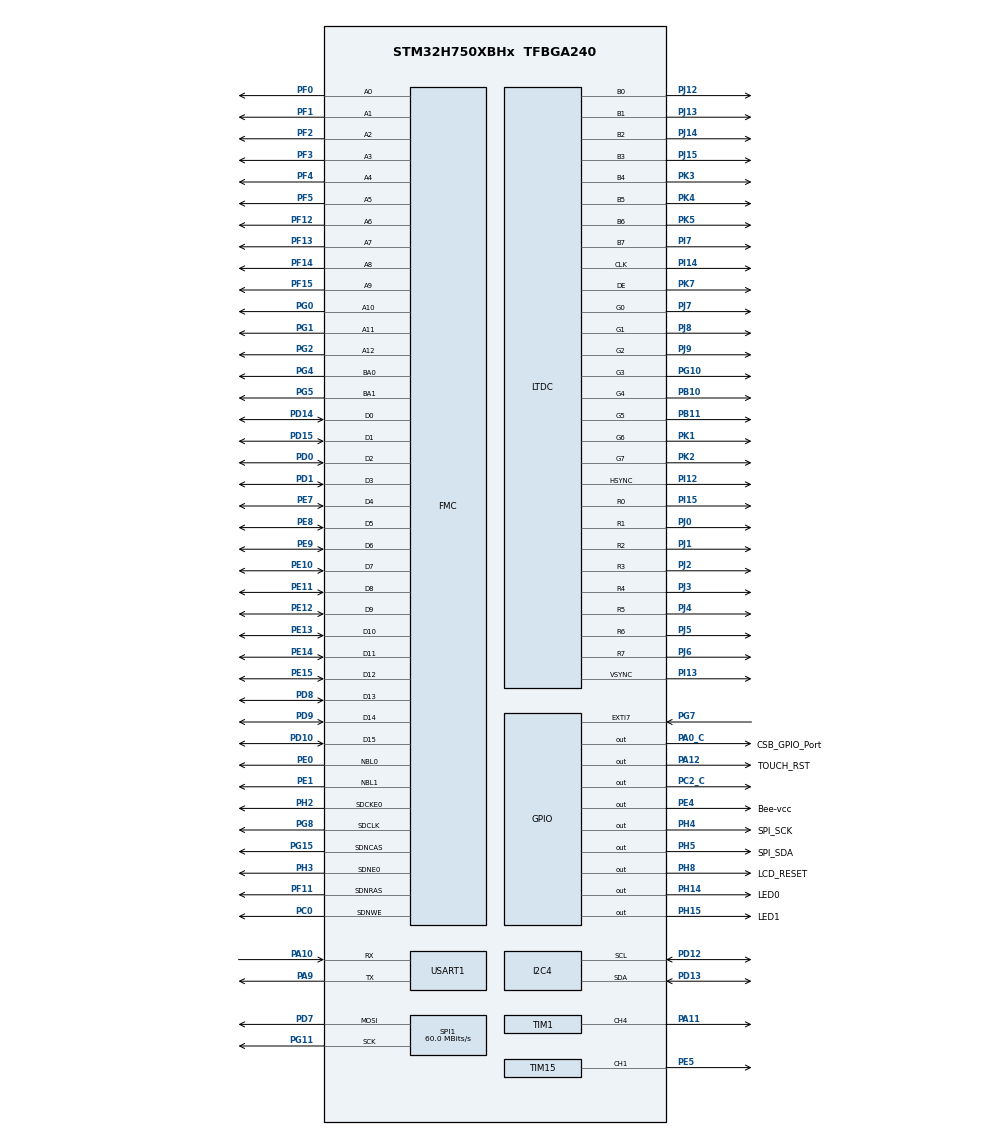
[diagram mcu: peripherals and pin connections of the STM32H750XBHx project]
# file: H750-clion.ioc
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CORTEX_M7.AccessPermission-Cortex_Memory_Protection_Unit_Region0_Settings=MPU_REGION_FULL_ACCESS
CORTEX_M7.BaseAddress-Cortex_Memory_Protection_Unit_Region0_Settings=0xC0000000
CORTEX_M7.CPU_DCache=Enabled
CORTEX_M7.CPU_ICache=Enabled
CORTEX_M7.Enable-Cortex_Memory_Protection_Unit_Region0_Settings=MPU_REGION_ENABLE
CORTEX_M7.IsCacheable-Cortex_Memory_Protection_Unit_Region0_Settings=MPU_ACCESS_CACHEABLE
CORTEX_M7.MPU_Control=MPU_PRIVILEGED_DEFAULT
CORTEX_M7.Size-Cortex_Memory_Protection_Unit_Region0_Settings=MPU_REGION_SIZE_32MB
DMA2D.ColorMode=DMA2D_OUTPUT_RGB565
Dma.Request0=USART1_RX
Dma.Request1=USART1_TX
Dma.USART1_RX.0.Direction=DMA_PERIPH_TO_MEMORY
Dma.USART1_RX.0.EventEnable=DISABLE
Dma.USART1_RX.0.FIFOMode=DMA_FIFOMODE_DISABLE
Dma.USART1_RX.0.Instance=DMA1_Stream0
Dma.USART1_RX.0.MemDataAlignment=DMA_MDATAALIGN_BYTE
Dma.USART1_RX.0.MemInc=DMA_MINC_ENABLE
Dma.USART1_RX.0.Mode=DMA_NORMAL
Dma.USART1_RX.0.PeriphDataAlignment=DMA_PDATAALIGN_BYTE
Dma.USART1_RX.0.PeriphInc=DMA_PINC_DISABLE
Dma.USART1_RX.0.Polarity=HAL_DMAMUX_REQ_GEN_RISING
Dma.USART1_RX.0.Priority=DMA_PRIORITY_LOW
Dma.USART1_RX.0.RequestNumber=1
Dma.USART1_RX.0.SignalID=NONE
Dma.USART1_RX.0.SyncEnable=DISABLE
Dma.USART1_RX.0.SyncPolarity=HAL_DMAMUX_SYNC_NO_EVENT
Dma.USART1_RX.0.SyncRequestNumber=1
Dma.USART1_RX.0.SyncSignalID=NONE
Dma.USART1_TX.1.Direction=DMA_MEMORY_TO_PERIPH
Dma.USART1_TX.1.EventEnable=DISABLE
Dma.USART1_TX.1.FIFOMode=DMA_FIFOMODE_DISABLE
Dma.USART1_TX.1.Instance=DMA1_Stream1
Dma.USART1_TX.1.MemDataAlignment=DMA_MDATAALIGN_BYTE
Dma.USART1_TX.1.MemInc=DMA_MINC_ENABLE
Dma.USART1_TX.1.Mode=DMA_NORMAL
Dma.USART1_TX.1.PeriphDataAlignment=DMA_PDATAALIGN_BYTE
Dma.USART1_TX.1.PeriphInc=DMA_PINC_DISABLE
Dma.USART1_TX.1.Polarity=HAL_DMAMUX_REQ_GEN_RISING
Dma.USART1_TX.1.Priority=DMA_PRIORITY_LOW
Dma.USART1_TX.1.RequestNumber=1
Dma.USART1_TX.1.SignalID=NONE
Dma.USART1_TX.1.SyncEnable=DISABLE
Dma.USART1_TX.1.SyncPolarity=HAL_DMAMUX_SYNC_NO_EVENT
Dma.USART1_TX.1.SyncRequestNumber=1
Dma.USART1_TX.1.SyncSignalID=NONE
FMC.CASLatency1=FMC_SDRAM_CAS_LATENCY_3
FMC.ColumnBitsNumber1=FMC_SDRAM_COLUMN_BITS_NUM_9
FMC.ExitSelfRefreshDelay1=7
FMC.LoadToActiveDelay1=2
FMC.RCDDelay1=2
FMC.RPDelay1=2
FMC.RPDelay2=2
FMC.ReadBurst1=FMC_SDRAM_RBURST_ENABLE
FMC.ReadBurst2=FMC_SDRAM_RBURST_ENABLE
FMC.ReadPipeDelay1=FMC_SDRAM_RPIPE_DELAY_1
FMC.ReadPipeDelay2=FMC_SDRAM_RPIPE_DELAY_1
FMC.RowCycleDelay1=7
FMC.RowCycleDelay2=7
FMC.SDClockPeriod1=FMC_SDRAM_CLOCK_PERIOD_2
FMC.SDClockPeriod2=FMC_SDRAM_CLOCK_PERIOD_2
FMC.SelfRefreshTime1=4
FMC.WriteRecoveryTime1=3
I2C4.Speed=100
I2C4.Timing=0x307075B1
LTDC.ActiveH=640
LTDC.ActiveW=480
LTDC.Alpha0_L0=0
LTDC.Alpha_L0=255
LTDC.BlendingFactor1_L0=LTDC_BLENDING_FACTOR1_CA
LTDC.BlendingFactor2_L0=LTDC_BLENDING_FACTOR2_CA
LTDC.Blue_L0=0
LTDC.DEPolarity=LTDC_DEPOLARITY_AL
LTDC.FBStartAdress_L0=0xC0000000
LTDC.Green=255
LTDC.HBP=30
LTDC.HFP=12
LTDC.HSync=1
LTDC.ImageHeight_L0=640
LTDC.ImageWidth_L0=480
LTDC.Layers=0
LTDC.PCPolarity=LTDC_PCPOLARITY_IIPC
LTDC.PixelFormat_L0=LTDC_PIXEL_FORMAT_RGB565
LTDC.VBP=30
LTDC.VFP=12
LTDC.VSync=6
LTDC.WindowX1_L0=480
LTDC.WindowY1_L0=640
Mcu.Family=STM32H7
Mcu.Name=STM32H750XBHx
Mcu.Package=TFBGA240
NVIC.DMA1_Stream0_IRQn=true\:0\:0\:false\:false\:true\:false\:true\:true
NVIC.DMA1_Stream1_IRQn=true\:0\:0\:true\:false\:true\:false\:true\:true
NVIC.DMA2D_IRQn=true\:2\:0\:true\:false\:true\:true\:true\:true
NVIC.EXTI9_5_IRQn=true\:5\:0\:true\:false\:true\:true\:true\:true
NVIC.I2C4_ER_IRQn=true\:3\:0\:true\:false\:true\:true\:true\:true
NVIC.PriorityGroup=NVIC_PRIORITYGROUP_4
NVIC.TIM15_IRQn=true\:3\:0\:true\:false\:true\:true\:true\:true
NVIC.TIM6_DAC_IRQn=true\:2\:0\:true\:false\:true\:true\:true\:true
NVIC.TIM7_IRQn=true\:2\:0\:true\:false\:true\:true\:true\:true
NVIC.TIM8_TRG_COM_TIM14_IRQn=true\:5\:0\:true\:false\:true\:true\:true\:true
NVIC.TIM8_UP_TIM13_IRQn=true\:3\:0\:true\:true\:true\:1\:true\:true\:true
NVIC.USART1_IRQn=true\:0\:0\:true\:false\:true\:true\:true\:true
PA0_C.GPIO_Label=CSB_GPIO_Port
PA0_C.GPIO_ModeDefaultOutputPP=GPIO_MODE_OUTPUT_PP
PA0_C.GPIO_PuPd=GPIO_NOPULL
PA0_C.GPIO_Speed=GPIO_SPEED_FREQ_VERY_HIGH
PA0_C.PinState=GPIO_PIN_SET
PA0_C.Signal=GPIO_Output
PA10.GPIO_PuPd=GPIO_PULLUP
PA10.GPIO_Speed=GPIO_SPEED_FREQ_MEDIUM
PA10.Mode=Asynchronous
PA10.Signal=USART1_RX
PA11.Signal=S_TIM1_CH4
PA12.GPIO_Label=TOUCH_RST
PA12.GPIO_PuPd=GPIO_PULLDOWN
PA12.Signal=GPIO_Output
PA13\ (JTMS/SWDIO).Mode=Serial_Wire
PA13\ (JTMS/SWDIO).Signal=DEBUG_JTMS-SWDIO
PA14\ (JTCK/SWCLK).Mode=Serial_Wire
PA14\ (JTCK/SWCLK).Signal=DEBUG_JTCK-SWCLK
PA9.GPIO_PuPd=GPIO_PULLUP
PA9.GPIO_Speed=GPIO_SPEED_FREQ_MEDIUM
PA9.Mode=Asynchronous
PA9.Signal=USART1_TX
PB10.GPIO_Speed=GPIO_SPEED_FREQ_VERY_HIGH
PB10.Mode=RGB888
PB10.Signal=LTDC_G4
PB11.GPIO_Speed=GPIO_SPEED_FREQ_VERY_HIGH
PB11.Mode=RGB888
PB11.Signal=LTDC_G5
PC0.Signal=FMC_SDNWE
PC14-OSC32_IN\ (OSC32_IN).Mode=LSE-External-Oscillator
PC14-OSC32_IN\ (OSC32_IN).Signal=RCC_OSC32_IN
PC15-OSC32_OUT\ (OSC32_OUT).Mode=LSE-External-Oscillator
PC15-OSC32_OUT\ (OSC32_OUT).Signal=RCC_OSC32_OUT
PC2_C.Signal=GPIO_Output
PD0.Signal=FMC_D2_DA2
PD1.Signal=FMC_D3_DA3
PD10.Signal=FMC_D15_DA15
PD12.Mode=I2C
PD12.Signal=I2C4_SCL
PD13.Mode=I2C
PD13.Signal=I2C4_SDA
PD14.Signal=FMC_D0_DA0
PD15.Signal=FMC_D1_DA1
PD7.Mode=TX_Only_Simplex_Unidirect_Master
PD7.Signal=SPI1_MOSI
PD8.Signal=FMC_D13_DA13
PD9.Signal=FMC_D14_DA14
PE0.Signal=FMC_NBL0
PE1.Signal=FMC_NBL1
PE10.Signal=FMC_D7_DA7
PE11.Signal=FMC_D8_DA8
PE12.Signal=FMC_D9_DA9
PE13.Signal=FMC_D10_DA10
PE14.Signal=FMC_D11_DA11
PE15.Signal=FMC_D12_DA12
PE4.GPIO_Label=Bee-vcc
PE4.GPIO_ModeDefaultOutputPP=GPIO_MODE_OUTPUT_PP
PE4.GPIO_PuPd=GPIO_NOPULL
PE4.PinState=GPIO_PIN_SET
PE4.Signal=GPIO_Output
PE5.Signal=S_TIM15_CH1
PE7.Signal=FMC_D4_DA4
PE8.Signal=FMC_D5_DA5
PE9.Signal=FMC_D6_DA6
PF0.Signal=FMC_A0
PF1.Signal=FMC_A1
PF11.Signal=FMC_SDNRAS
PF12.Signal=FMC_A6
PF13.Signal=FMC_A7
PF14.Signal=FMC_A8
PF15.Signal=FMC_A9
PF2.Signal=FMC_A2
PF3.Signal=FMC_A3
PF4.Signal=FMC_A4
PF5.Signal=FMC_A5
PG0.Signal=FMC_A10
PG1.Signal=FMC_A11
PG10.GPIO_Speed=GPIO_SPEED_FREQ_VERY_HIGH
PG10.Mode=RGB888
PG10.Signal=LTDC_G3
PG11.Mode=TX_Only_Simplex_Unidirect_Master
PG11.Signal=SPI1_SCK
PG15.Signal=FMC_SDNCAS
PG2.Signal=FMC_A12
PG4.Signal=FMC_A14_BA0
PG5.Signal=FMC_A15_BA1
PG7.GPIO_ModeDefaultEXTI=GPIO_MODE_IT_FALLING
PG7.GPIO_PuPd=GPIO_NOPULL
PG7.Signal=GPXTI7
PG8.Signal=FMC_SDCLK
PH0-OSC_IN\ (PH0).Mode=HSE-External-Oscillator
PH0-OSC_IN\ (PH0).Signal=RCC_OSC_IN
PH1-OSC_OUT\ (PH1).Mode=HSE-External-Oscillator
PH1-OSC_OUT\ (PH1).Signal=RCC_OSC_OUT
PH14.GPIO_Label=LED0
PH14.PinState=GPIO_PIN_SET
PH14.Signal=GPIO_Output
PH15.GPIO_Label=LED1
PH15.PinState=GPIO_PIN_SET
PH15.Signal=GPIO_Output
PH2.Mode=SdramChipSelect1_1
PH2.Signal=FMC_SDCKE0
PH3.Mode=SdramChipSelect1_1
PH3.Signal=FMC_SDNE0
PH4.GPIO_Label=SPI_SCK
PH4.GPIO_PuPd=GPIO_PULLUP
PH4.GPIO_Speed=GPIO_SPEED_FREQ_VERY_HIGH
PH4.PinState=GPIO_PIN_SET
PH4.Signal=GPIO_Output
PH5.GPIO_Label=SPI_SDA
PH5.GPIO_PuPd=GPIO_PULLUP
PH5.GPIO_Speed=GPIO_SPEED_FREQ_VERY_HIGH
PH5.PinState=GPIO_PIN_SET
PH5.Signal=GPIO_Output
PH8.GPIO_Label=LCD_RESET
PH8.GPIO_ModeDefaultOutputPP=GPIO_MODE_OUTPUT_PP
PH8.GPIO_PuPd=GPIO_PULLUP
PH8.GPIO_Speed=GPIO_SPEED_FREQ_VERY_HIGH
PH8.PinState=GPIO_PIN_SET
PH8.Signal=GPIO_Output
PI12.GPIO_Speed=GPIO_SPEED_FREQ_VERY_HIGH
PI12.Mode=RGB888
PI12.Signal=LTDC_HSYNC
PI13.GPIO_Speed=GPIO_SPEED_FREQ_VERY_HIGH
PI13.Mode=RGB888
PI13.Signal=LTDC_VSYNC
PI14.GPIO_Speed=GPIO_SPEED_FREQ_VERY_HIGH
PI14.Mode=RGB888
PI14.Signal=LTDC_CLK
PI15.GPIO_Speed=GPIO_SPEED_FREQ_VERY_HIGH
PI15.Mode=RGB888
PI15.Signal=LTDC_R0
PI7.GPIO_Speed=GPIO_SPEED_FREQ_VERY_HIGH
PI7.Mode=RGB888
PI7.Signal=LTDC_B7
PJ0.GPIO_Speed=GPIO_SPEED_FREQ_VERY_HIGH
PJ0.Mode=RGB888
PJ0.Signal=LTDC_R1
PJ1.GPIO_Speed=GPIO_SPEED_FREQ_VERY_HIGH
PJ1.Mode=RGB888
PJ1.Signal=LTDC_R2
PJ12.GPIO_Speed=GPIO_SPEED_FREQ_VERY_HIGH
PJ12.Mode=RGB888
PJ12.Signal=LTDC_B0
PJ13.GPIO_Speed=GPIO_SPEED_FREQ_VERY_HIGH
PJ13.Mode=RGB888
PJ13.Signal=LTDC_B1
PJ14.GPIO_Speed=GPIO_SPEED_FREQ_VERY_HIGH
PJ14.Mode=RGB888
PJ14.Signal=LTDC_B2
PJ15.GPIO_Speed=GPIO_SPEED_FREQ_VERY_HIGH
PJ15.Mode=RGB888
PJ15.Signal=LTDC_B3
PJ2.GPIO_Speed=GPIO_SPEED_FREQ_VERY_HIGH
PJ2.Mode=RGB888
PJ2.Signal=LTDC_R3
PJ3.GPIO_Speed=GPIO_SPEED_FREQ_VERY_HIGH
PJ3.Mode=RGB888
PJ3.Signal=LTDC_R4
PJ4.GPIO_Speed=GPIO_SPEED_FREQ_VERY_HIGH
PJ4.Mode=RGB888
PJ4.Signal=LTDC_R5
PJ5.GPIO_Speed=GPIO_SPEED_FREQ_VERY_HIGH
PJ5.Mode=RGB888
PJ5.Signal=LTDC_R6
PJ6.GPIO_Speed=GPIO_SPEED_FREQ_VERY_HIGH
PJ6.Mode=RGB888
PJ6.Signal=LTDC_R7
PJ7.GPIO_Speed=GPIO_SPEED_FREQ_VERY_HIGH
PJ7.Mode=RGB888
PJ7.Signal=LTDC_G0
PJ8.GPIO_Speed=GPIO_SPEED_FREQ_VERY_HIGH
PJ8.Mode=RGB888
PJ8.Signal=LTDC_G1
PJ9.GPIO_Speed=GPIO_SPEED_FREQ_VERY_HIGH
PJ9.Mode=RGB888
PJ9.Signal=LTDC_G2
PK1.GPIO_Speed=GPIO_SPEED_FREQ_VERY_HIGH
PK1.Mode=RGB888
PK1.Signal=LTDC_G6
PK2.GPIO_Speed=GPIO_SPEED_FREQ_VERY_HIGH
PK2.Mode=RGB888
PK2.Signal=LTDC_G7
PK3.GPIO_Speed=GPIO_SPEED_FREQ_VERY_HIGH
PK3.Mode=RGB888
PK3.Signal=LTDC_B4
PK4.GPIO_Speed=GPIO_SPEED_FREQ_VERY_HIGH
PK4.Mode=RGB888
PK4.Signal=LTDC_B5
PK5.GPIO_Speed=GPIO_SPEED_FREQ_VERY_HIGH
PK5.Mode=RGB888
PK5.Signal=LTDC_B6
PK7.GPIO_Speed=GPIO_SPEED_FREQ_VERY_HIGH
PK7.Mode=RGB888
PK7.Signal=LTDC_DE
ProjectManager.HeapSize=0x2000
ProjectManager.StackSize=0x3000
ProjectManager.TargetToolchain=CMake
RCC.ADCFreq_Value=120000000
RCC.APB1Freq_Value=120000000
RCC.APB2Freq_Value=120000000
RCC.APB3Freq_Value=120000000
RCC.APB4Freq_Value=120000000
RCC.CortexFreq_Value=480000000
RCC.D1PPRE=RCC_APB3_DIV2
RCC.D2PPRE1=RCC_APB1_DIV2
RCC.D2PPRE2=RCC_APB2_DIV2
RCC.D3PPRE=RCC_APB4_DIV2
RCC.DIVM1=5
RCC.DIVM2=25
RCC.DIVM3=25
RCC.DIVN1=192
RCC.DIVN2=240
RCC.DIVN3=400
RCC.DIVQ1=4
RCC.DIVR3=20
RCC.HCLKFreq_Value=240000000
RCC.HPRE=RCC_HCLK_DIV2
RCC.PLL2FRACN=0
RCC.PLL3FRACN=0
RCC.PLLFRACN=0
RCC.PLLSourceVirtual=RCC_PLLSOURCE_HSE
RCC.ProductRev=revV
RCC.SPI123CLockSelection=RCC_SPI123CLKSOURCE_PLL2
RCC.SYSCLKFreq_VALUE=480000000
RCC.SYSCLKSource=RCC_SYSCLKSOURCE_PLLCLK
RCC.USBFreq_Value=240000000
SH.FMC_A0.0=FMC_A0,13b-sda1
SH.FMC_A1.0=FMC_A1,13b-sda1
SH.FMC_A10.0=FMC_A10,13b-sda1
SH.FMC_A11.0=FMC_A11,13b-sda1
SH.FMC_A12.0=FMC_A12,13b-sda1
SH.FMC_A14_BA0.0=FMC_BA0,FourSdramBanks1
SH.FMC_A15_BA1.0=FMC_BA1,FourSdramBanks1
SH.FMC_A2.0=FMC_A2,13b-sda1
SH.FMC_A3.0=FMC_A3,13b-sda1
SH.FMC_A4.0=FMC_A4,13b-sda1
SH.FMC_A5.0=FMC_A5,13b-sda1
SH.FMC_A6.0=FMC_A6,13b-sda1
SH.FMC_A7.0=FMC_A7,13b-sda1
SH.FMC_A8.0=FMC_A8,13b-sda1
SH.FMC_A9.0=FMC_A9,13b-sda1
SH.FMC_D0_DA0.0=FMC_D0,sd-16b-d1
SH.FMC_D10_DA10.0=FMC_D10,sd-16b-d1
SH.FMC_D11_DA11.0=FMC_D11,sd-16b-d1
SH.FMC_D12_DA12.0=FMC_D12,sd-16b-d1
SH.FMC_D13_DA13.0=FMC_D13,sd-16b-d1
SH.FMC_D14_DA14.0=FMC_D14,sd-16b-d1
SH.FMC_D15_DA15.0=FMC_D15,sd-16b-d1
SH.FMC_D1_DA1.0=FMC_D1,sd-16b-d1
SH.FMC_D2_DA2.0=FMC_D2,sd-16b-d1
SH.FMC_D3_DA3.0=FMC_D3,sd-16b-d1
SH.FMC_D4_DA4.0=FMC_D4,sd-16b-d1
SH.FMC_D5_DA5.0=FMC_D5,sd-16b-d1
SH.FMC_D6_DA6.0=FMC_D6,sd-16b-d1
SH.FMC_D7_DA7.0=FMC_D7,sd-16b-d1
SH.FMC_D8_DA8.0=FMC_D8,sd-16b-d1
SH.FMC_D9_DA9.0=FMC_D9,sd-16b-d1
SH.FMC_NBL0.0=FMC_NBL0,Sd2ByteEnable1
SH.FMC_NBL1.0=FMC_NBL1,Sd2ByteEnable1
SH.FMC_SDCLK.0=FMC_SDCLK,13b-sda1
SH.FMC_SDNCAS.0=FMC_SDNCAS,13b-sda1
SH.FMC_SDNRAS.0=FMC_SDNRAS,13b-sda1
SH.FMC_SDNWE.0=FMC_SDNWE,13b-sda1
SH.S_TIM15_CH1.0=TIM15_CH1,PWM Generation1 CH1
SH.S_TIM1_CH4.0=TIM1_CH4,PWM Generation4 CH4
SPI1.CalculateBaudRate=60.0 MBits/s
SPI1.Direction=SPI_DIRECTION_2LINES_TXONLY
SPI1.Mode=SPI_MODE_MASTER
SPI1.VirtualType=VM_MASTER
TIM1.Channel-PWM\ Generation4\ CH4=TIM_CHANNEL_4
TIM1.Period=99
TIM1.Prescaler=47
TIM13.Period=1000
TIM13.Prescaler=23999
TIM14.Period=9999
TIM14.Prescaler=24000
TIM15.Channel-PWM\ Generation1\ CH1=TIM_CHANNEL_1
TIM15.OCMode_PWM-PWM\ Generation1\ CH1=TIM_OCMODE_PWM2
TIM15.Period=99
TIM15.Prescaler=888
TIM15.Pulse-PWM\ Generation1\ CH1=50
TIM6.AutoReloadPreload=TIM_AUTORELOAD_PRELOAD_DISABLE
TIM6.Period=65535
TIM6.Prescaler=239
TIM7.AutoReloadPreload=TIM_AUTORELOAD_PRELOAD_ENABLE
TIM7.Period=1999
TIM7.Prescaler=2399
USART1.VirtualMode-Asynchronous=VM_ASYNC
VP_DMA2D_VS_DMA2D.Mode=DMA2D_Activate
VP_TIM13_VS_ClockSourceINT.Mode=Enable_Timer
VP_TIM14_VS_ClockSourceINT.Mode=Enable_Timer
VP_TIM15_VS_ClockSourceINT.Mode=Internal
VP_TIM6_VS_ClockSourceINT.Mode=Enable_Timer
VP_TIM7_VS_ClockSourceINT.Mode=Enable_Timer
board=custom

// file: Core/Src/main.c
/* USER CODE BEGIN Header */
/**
 ******************************************************************************
 * @file           : main.c
 * @brief          : Main program body
 ******************************************************************************
 * @attention
 *
 * Copyright (c) 2024 STMicroelectronics.
 * All rights reserved.
 *
 * This software is licensed under terms that can be found in the LICENSE file
 * in the root directory of this software component.
 * If no LICENSE file comes with this software, it is provided AS-IS.
 *
 ******************************************************************************
 */
/* USER CODE END Header */
#include "main.h"
#include "dma.h"
#include "dma2d.h"
#include "i2c.h"
#include "ltdc.h"
#include "spi.h"
#include "tim.h"
#include "usart.h"
#include "gpio.h"
#include "fmc.h"

/* USER CODE BEGIN Includes */
#include "Lcd_int.h"
#include "ui.h"
#include "touch.h"
// #include "touch.h"
#include "lv_port_indev_template.h"
#include "lv_port_disp_template.h"
#include "screen.h"
/* USER CODE END Includes */

/* USER CODE BEGIN PV */
extern uint8_t Tim7_flag_60ms;
 extern uint32_t save_picture_time;
extern uint16_t Tim7_flag_1s;
extern TIM_HandleTypeDef htim1;

#if 0
extern RingQueue uartRingQueue; // 初始化队�???
extern UART_RX_TypeDef uart_rx_data_t[UART_BUFFER_QUANTITY]; // 双缓冲数据存�???
extern uint8_t uart_buff_ctrl; // 缓冲区索�???
#endif
/* USER CODE END PV */

void SystemClock_Config(void);
static void MPU_Config(void);
static void MX_NVIC_Init(void);

/* USER CODE BEGIN 0 */
/* Kept in internal RAM for debugger inspection after a restart. */
volatile uint32_t screen_reset_flags;
volatile uint32_t screen_boot_stage;

static void screen_watchdog_feed(void)
{
  IWDG1->KR = 0xAAAAU;
}

static void screen_watchdog_start(void)
{
  screen_reset_flags = RCC->RSR;
  __HAL_RCC_CLEAR_RESET_FLAGS();
  /* Register sequence follows STM32H7 IWDG: start forces LSI on. No
   * dependency on HSE/PLL, SysTick, HAL initialization or external SDRAM.
   * 256 * (999 + 1) / nominal 32000 Hz = 8 s (LSI tolerance applies). */
  IWDG1->KR = 0xCCCCU;
  IWDG1->KR = 0x5555U;
  IWDG1->PR = 6U;
  IWDG1->RLR = 999U;
  /* Do not feed while waiting: IWDG itself resets a failed initialization. */
  while (IWDG1->SR != 0U) {}
  IWDG1->WINR = 0xFFFU;
  while (IWDG1->SR != 0U) {}
  screen_watchdog_feed();
}

static void screen_boot_progress(uint32_t stage)
{
  screen_boot_stage = stage;
  screen_watchdog_feed();
}

/* USER CODE END 0 */

int main(void)
{

  /* USER CODE BEGIN 1 */
  screen_watchdog_start();
  screen_boot_progress(1U);

  /* USER CODE END 1 */

  /* MPU Configuration--------------------------------------------------------*/
  MPU_Config();

  /* Enable the CPU Cache */

  /* Enable I-Cache---------------------------------------------------------*/
  SCB_EnableICache();

  /* Enable D-Cache---------------------------------------------------------*/
  SCB_EnableDCache();

  /* MCU Configuration--------------------------------------------------------*/

  /* Reset of all peripherals, Initializes the Flash interface and the Systick. */
  HAL_Init();

  /* Configure the system clock */
  SystemClock_Config();
  screen_boot_progress(2U);

  /* USER CODE BEGIN SysInit */
  HAL_SYSCFG_AnalogSwitchConfig(SYSCFG_SWITCH_PA0, SYSCFG_SWITCH_PA0_CLOSE); // ��������Ϊģ�⿪�أ���ʵ�ֲ�ͬ�Ĺ��ܡ����磬���Խ���������Ϊģ�����롢ģ���������??????���ӵ��ڲ���ģ��ģ�飨?? ADC��DAC �ȣ��ر� PA0 ����
  HAL_SYSCFG_AnalogSwitchConfig(SYSCFG_SWITCH_PC2, SYSCFG_SWITCH_PC2_CLOSE); // �ر� PC2 ���ӡ�
  /* USER CODE END SysInit */

  /* Initialize all configured peripherals */
  MX_GPIO_Init();
  MX_DMA_Init();
  MX_USART1_UART_Init();

  /* USART1 RX is already armed here. Send the power-on command before any
   * display, touch, timer or UI initialization can delay the handshake. */
  screenstart();
  uint32_t last_screenstart_time = HAL_GetTick();
  uint32_t language_wait_started = HAL_GetTick();

  /* Let the controller return the persisted language before LCD/LVGL can
   * construct a frame in the default language. USART1 RX DMA is active. */
  while (!screen_start_language_received() &&
         HAL_GetTick() - language_wait_started < 250U) {
    __WFI();
  }

  screen_boot_progress(3U);
  MX_TIM7_Init();
  MX_TIM15_Init();
  MX_DMA2D_Init();
  MX_FMC_Init();
  screen_boot_progress(4U);
  MX_LTDC_Init();
  MX_TIM14_Init();
  MX_TIM6_Init();
  MX_SPI1_Init();
  MX_I2C4_Init();
  MX_TIM13_Init();
  MX_TIM1_Init();

  /* Initialize interrupts */
  MX_NVIC_Init();
  /* USER CODE BEGIN 2 */
  /* LCD reset/init is performed once by lv_port_disp_init(). */
  GT911_Init();
  screen_boot_progress(5U);
  lv_init();
  lv_port_disp_init();
  screen_boot_progress(6U);
  lv_port_indev_init();
  screen_finish_startup_language_preload();
  ui_init();
  screen_boot_progress(7U);
  //HAL_TIM_PWM_Start(&htim15, TIM_CHANNEL_1);//start PWM for Beep
  /* Backlight must not depend on an LTDC reload acknowledgement. */
  __HAL_TIM_SET_COMPARE(&htim1, TIM_CHANNEL_4, 60);
  HAL_TIM_PWM_Start(&htim1, TIM_CHANNEL_4);
  __HAL_TIM_MOE_ENABLE(&htim1);
  /* USER CODE END 2 */

  /* Infinite loop */
  while (1)
  {

    /* USER CODE BEGIN 3 */
		HAL_GPIO_TogglePin(GPIOH, GPIO_PIN_14);
     //HAL_Delay(90);
#if 0
        UART_RX_TypeDef *frameData;
        while ((frameData = RingQueue_Pop(&uartRingQueue)) != NULL) {
            Serial_data_stream_parsing(frameData); // 解析数据�???
        }
#endif
        uint8_t serial_data[128];
        size_t received;
        /* Bound UART work so a noisy/continuous stream cannot starve UI
         * progress and watchdog servicing. Remaining bytes stay queued. */
        for (uint8_t batch = 0U; batch < 4U; ++batch) {
            received = ScreenUart_Read(serial_data, sizeof(serial_data));
            if (received == 0U) break;
            Serial_data_stream_parsing(serial_data, received);
        }
        GT911_Process();
        screen_treatment_ack_tick();
     /* Apply every pending startup setting before LVGL's first draw. */
     lv_timer_handler();
        screen_fault_popup_tick();
        screen_refresh_runtime_ui();

    HAL_GPIO_TogglePin(GPIOH, GPIO_PIN_15);
if (HAL_GetTick() - save_picture_time >= 1000) {
   lv_obj_add_flag(ui_Image107,
                   LV_OBJ_FLAG_HIDDEN); /// Flags
}
work_flinsh();
        if (!screen_start_ack_received() &&
            (HAL_GetTick() - last_screenstart_time >= 1000U)) {
            screenstart();
            last_screenstart_time = HAL_GetTick();
        }
        /* Only a completed communication/touch/UI loop proves liveness.
         * Never feed from SysTick, interrupts, or peripheral wait loops. */
        screen_boot_progress(8U);
	}
  /* USER CODE END 3 */
}

void SystemClock_Config(void)
{
  RCC_OscInitTypeDef RCC_OscInitStruct = {0};
  RCC_ClkInitTypeDef RCC_ClkInitStruct = {0};

  /** Supply configuration update enable
  */
  HAL_PWREx_ConfigSupply(PWR_LDO_SUPPLY);

  /** Configure the main internal regulator output voltage
  */
  __HAL_PWR_VOLTAGESCALING_CONFIG(PWR_REGULATOR_VOLTAGE_SCALE0);

  while(!__HAL_PWR_GET_FLAG(PWR_FLAG_VOSRDY)) {}

  /** Initializes the RCC Oscillators according to the specified parameters
  * in the RCC_OscInitTypeDef structure.
  */
  RCC_OscInitStruct.OscillatorType = RCC_OSCILLATORTYPE_HSE;
  RCC_OscInitStruct.HSEState = RCC_HSE_ON;
  RCC_OscInitStruct.PLL.PLLState = RCC_PLL_ON;
  RCC_OscInitStruct.PLL.PLLSource = RCC_PLLSOURCE_HSE;
  RCC_OscInitStruct.PLL.PLLM = 5;
  RCC_OscInitStruct.PLL.PLLN = 192;
  RCC_OscInitStruct.PLL.PLLP = 2;
  RCC_OscInitStruct.PLL.PLLQ = 4;
  RCC_OscInitStruct.PLL.PLLR = 2;
  RCC_OscInitStruct.PLL.PLLRGE = RCC_PLL1VCIRANGE_2;
  RCC_OscInitStruct.PLL.PLLVCOSEL = RCC_PLL1VCOWIDE;
  RCC_OscInitStruct.PLL.PLLFRACN = 0;
  if (HAL_RCC_OscConfig(&RCC_OscInitStruct) != HAL_OK)
  {
    Error_Handler();
  }

  /** Initializes the CPU, AHB and APB buses clocks
  */
  RCC_ClkInitStruct.ClockType = RCC_CLOCKTYPE_HCLK|RCC_CLOCKTYPE_SYSCLK
                              |RCC_CLOCKTYPE_PCLK1|RCC_CLOCKTYPE_PCLK2
                              |RCC_CLOCKTYPE_D3PCLK1|RCC_CLOCKTYPE_D1PCLK1;
  RCC_ClkInitStruct.SYSCLKSource = RCC_SYSCLKSOURCE_PLLCLK;
  RCC_ClkInitStruct.SYSCLKDivider = RCC_SYSCLK_DIV1;
  RCC_ClkInitStruct.AHBCLKDivider = RCC_HCLK_DIV2;
  RCC_ClkInitStruct.APB3CLKDivider = RCC_APB3_DIV2;
  RCC_ClkInitStruct.APB1CLKDivider = RCC_APB1_DIV2;
  RCC_ClkInitStruct.APB2CLKDivider = RCC_APB2_DIV2;
  RCC_ClkInitStruct.APB4CLKDivider = RCC_APB4_DIV2;

  if (HAL_RCC_ClockConfig(&RCC_ClkInitStruct, FLASH_LATENCY_4) != HAL_OK)
  {
    Error_Handler();
  }
}

/**
  * @brief NVIC Configuration.
  * @retval None
  */
static void MX_NVIC_Init(void)
{
  /* TIM8_UP_TIM13_IRQn interrupt configuration */
  HAL_NVIC_SetPriority(TIM8_UP_TIM13_IRQn, 3, 0);
  HAL_NVIC_EnableIRQ(TIM8_UP_TIM13_IRQn);
}

 /* MPU Configuration */

void MPU_Config(void)
{
  MPU_Region_InitTypeDef MPU_InitStruct = {0};

  /* Disables the MPU */
  HAL_MPU_Disable();

  /** Initializes and configures the Region and the memory to be protected
  */
  MPU_InitStruct.Enable = MPU_REGION_ENABLE;
  MPU_InitStruct.Number = MPU_REGION_NUMBER0;
  MPU_InitStruct.BaseAddress = 0xC0000000;
  MPU_InitStruct.Size = MPU_REGION_SIZE_32MB;
  MPU_InitStruct.SubRegionDisable = 0x0;
  MPU_InitStruct.TypeExtField = MPU_TEX_LEVEL0;
  MPU_InitStruct.AccessPermission = MPU_REGION_FULL_ACCESS;
  MPU_InitStruct.DisableExec = MPU_INSTRUCTION_ACCESS_ENABLE;
  MPU_InitStruct.IsShareable = MPU_ACCESS_NOT_SHAREABLE;
  MPU_InitStruct.IsCacheable = MPU_ACCESS_CACHEABLE;
  MPU_InitStruct.IsBufferable = MPU_ACCESS_NOT_BUFFERABLE;

  HAL_MPU_ConfigRegion(&MPU_InitStruct);
  /* Enables the MPU */
  HAL_MPU_Enable(MPU_PRIVILEGED_DEFAULT);

}

void Error_Handler(void)
{
  __disable_irq();
  while (1)
  {
  }
}
